# H616 register map
Vendor: Allwinner; Series: H616; File version: 0.1
CPU: other 0, little endian, MPU, no FPU, 0 interrupt priority bits
Registers are 32-bit, read-write, reset 0x0 unless marked. A register's access mark holds for its fields unless they carry their own. Offsets are from the block's base; [hi:lo] are bit positions; {n}, {i} and the like mark numbered series.

## C0_CPUX_CFG
Base 0x09010000
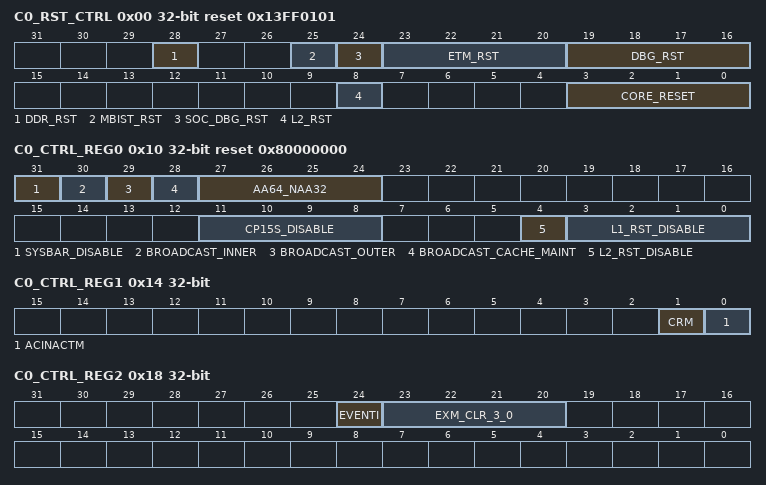
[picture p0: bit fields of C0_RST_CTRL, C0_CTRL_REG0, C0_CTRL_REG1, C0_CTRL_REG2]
0x00 C0_RST_CTRL reset 0x13FF0101 — Cluster 0 Reset Control Register
  [28] DDR_RST — AXI2MBUS Logic Circuit Reset 0: assert 1: de-assert
    0=assert; 1=deassert
  [25] MBIST_RST — CPUBIST Reset The reset signal is for test 0: assert 1: de-assert
    0=assert; 1=deassert
  [24] SOC_DBG_RST — Cluster SOC Debug Reset 0: assert 1: de-assert
    0=assert; 1=deassert
  [23:20] ETM_RST — Cluster ETM Reset Assert 0: assert 1: de-assert
  [19:16] DBG_RST — Cluster Debug Reset Assert 0: assert 1: de-assert
  [8] L2_RST — Cluster L2 Cache Reset 0: assert 1: de-assert
    0=assert; 1=deassert
  [3:0] CORE_RESET — Cluster CPU[3:0] Reset Assert 0: assert 1: de-assert
0x10 C0_CTRL_REG0 reset 0x80000000 — Cluster 0 Control Register0
  [31] SYSBAR_DISABLE — Disable broadcasting of barriers onto system bus 0: Barriers are broadcasted onto system bus, this requires an AMBA4 interconnect 1: Barriers are not broadcasted onto the system bus. This is compatible with an AXI3 interconnect
    0=Barriers are broadcasted onto system bus, this requires an AMBA4 interconnect; 1=Barriers are not broadcasted onto the system bus. This is compatible with an AXI3 interconnect
  [30] BROADCAST_INNER — Enable broadcasting of inner shareable transactions 0: Inner shareable transactions are not broadcasted externally 1: Inner shareable transactions are broadcasted externally
    0=Inner shareable transactions are not broadcasted externally; 1=Inner shareable transactions are broadcasted externally
  [29] BROADCAST_OUTER — Enable broadcasting of outer shareable transactions 0: Outer Shareable transactions are not broadcasted externally 0: Outer Shareable transactions are broadcasted externally
    0=Outer Shareable transactions are not broadcasted externally; 0=Outer Shareable transactions are broadcasted externally
  [28] BROADCAST_CACHE_MAINT — Enable broadcasting of cache maintenance operations to downstream caches 0: Cache maintenance operations are not broadcasted to downstream caches 1: Cache maintenance operations are broadcasted to downstream caches
    0=Cache maintenance operations are not broadcasted to downstream caches; 1=Cache maintenance operations are broadcasted to downstream caches
  [27:24] AA64_NAA32 — AA64Naa32 Register width state 0 : AArch32 1 : AArch64 This pin is sampled only during reset of the processor
  [11:8] CP15S_DISABLE — Disable write access to some secure CP15 register.
  [4] L2_RST_DISABLE — Disable automatic L2 cache invalidate at reset 0: L2 cache is reset by hardware 1: L2 cache is not reset by hardware
    0=reset (L2 cache is reset by hardware); 1=not_reset (L2 cache is not reset by hardware)
  [3:0] L1_RST_DISABLE — Disable automatic Cluster CPU[3:0] L1 cache invalidate at reset: 0: L1 cache is reset by hardware. 1: L1 cache is not reset by hardware.
0x14 C0_CTRL_REG1 — Cluster 0 Control Register1
  [1] CRM — auto select slow frequency enable 0: disable auto select 1: enable auto select
    0=disable auto select; 1=enable auto select
  [0] ACINACTM — Snoop interface is inactive and no longer accepts request 0: Snoop interface is active 1: Snoop interface is inactive
    0=active (Snoop interface is active); 1=inactive (Snoop interface is inactive)
0x18 C0_CTRL_REG2 — Cluster 0 Control Register2
  [24] EVENTI — Event input for processor wake-up from WFE state. This bit must remain high for at least one clock cycle to be visible by the cores.
  [23:20] EXM_CLR_3_0 — EXM_CLR[3:0] Clear the status of interface.
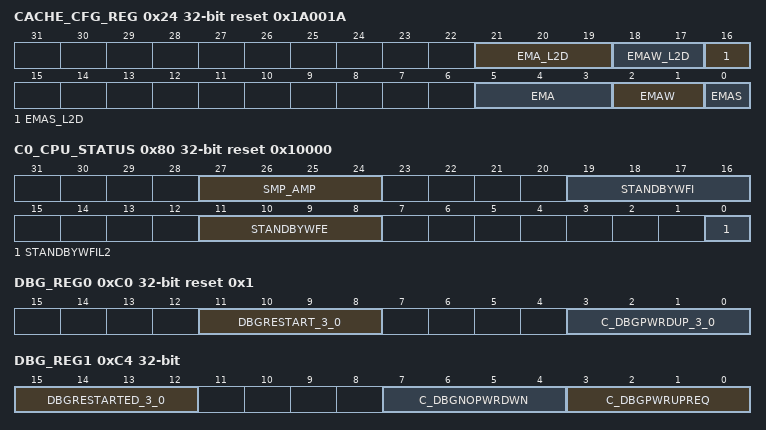
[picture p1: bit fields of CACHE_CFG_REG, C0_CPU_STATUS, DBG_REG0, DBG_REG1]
0x24 CACHE_CFG_REG reset 0x1A001A — Cache Configuration Register
  [21:19] EMA_L2D — L2 Cache SRAM EMA control port
  [18:17] EMAW_L2D — L2 Cache SRAM EMAW control port
  [16] EMAS_L2D — L2 Cache SRAM EMAS control port
  [5:3] EMA — Cache SRAM EMA control port
  [2:1] EMAW — Cache SRAM EMAW control port
  [0] EMAS — Cache SRAM EMAS control port
{0x40+8i} RVBARADDR{i}_L (i=0..3) — Reset Vector Base Address Register{i}_L
  [31:2] RVBARADDR_31_2 — RVBARADDR[31:2] Reset Vector Base Address[31:2] for executing in 64-bit state (AArch64) of CPU{i}.
{0x44+8i} RVBARADDR{i}_H (i=0..3) — Reset Vector Base Address Register{i}_H
  [7:0] RVBARADDR_39_32 — RVBARADDR[39:32] Reset Vector Base Address[39:32] for executing in 64-bit state (AArch64) of CPU{i}.
0x80 C0_CPU_STATUS reset 0x10000 — Cluster 0 CPU Status Register
  [27:24] SMP_AMP ro — CPU[3:0] is in Symmetric Multiprocessing mode or Asymmetric Multiprocessing mode. 0: AMP mode 1: SMP mode
  [19:16] STANDBYWFI ro — Indicates if Cluster CPU[3:0] is in WFI standby mode 0: Processor not in WFI standby mode. 1: Processor in WFI standby mode
  [11:8] STANDBYWFE ro — Indicates if Cluster CPU[3:0] is in the WFE standby mode 0: Processor not in WFE standby mode 1: Processor in WFE standby mode
  [0] STANDBYWFIL2 ro — Indicates if the Cluster L2 memory system is in WFI standby mode 0: Cluster L2 not in WFI standby mode 1: Cluster L2 in WFI standby mode
    0=Cluster L2 not in WFI standby mode; 1=Cluster L2 in WFI standby mode
0x84 L2_STATUS_REG — Cluster 0 L2 Status Register
  [9] EVENTO ro — Event output. This bit is asserted HIGH for 3 clock cycles when any core in the cluster executes an SEV instruction.
0xC0 DBG_REG0 reset 0x1 — Cluster 0 Debug Control Register0
  [11:8] DBGRESTART_3_0 — DBGRESTART[3:0] External restart requests.
  [3:0] C_DBGPWRDUP_3_0 — C_DBGPWRDUP[3:0] Cluster Powered-up 0: Core is powered down 1: Core is powered up
0xC4 DBG_REG1 — Cluster 0 Debug Control Register1
  [15:12] DBGRESTARTED_3_0 — DBGRESTARTED[3:0] Handshake for DBGRESTART.
  [7:4] C_DBGNOPWRDWN ro — No power-down request. Debugger has requested that processor is not powered down. Debug no power down[3:0].
  [3:0] C_DBGPWRUPREQ ro — Power up request Debug power up request[3:0] 0: Do not request that the core is powered up 1: Request that the core is powered up
